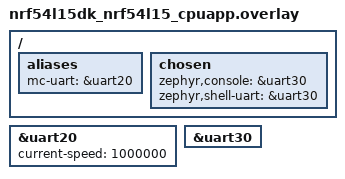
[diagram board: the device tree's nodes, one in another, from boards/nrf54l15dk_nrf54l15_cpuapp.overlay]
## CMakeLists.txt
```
# Copyright The Zephyr Project Contributors
# SPDX-License-Identifier: Apache-2.0

cmake_minimum_required(VERSION 3.28.0)
find_package(Zephyr REQUIRED HINTS $ENV{ZEPHYR_BASE})
project(mc_comm_stress)

target_sources(app PRIVATE
  src/main.c
)

if(CONFIG_TEST_MC_STRESS_UART)
  target_sources(app PRIVATE
    ../console_prefix.c
    src/transport_uart.c
  )
else()
  target_sources(app PRIVATE src/transport_native.c)
endif()
```

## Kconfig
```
# Copyright The Zephyr Project Contributors
# SPDX-License-Identifier: Apache-2.0

mainmenu "MC communication stress tests"

source "Kconfig.zephyr"

config TEST_MC_STRESS_UART
	bool "Use the two-board UART transport"
	depends on SERIAL
	help
	  Run the communication tests between two boards over UART.

config TEST_MC_STRESS_SENDER
	bool "Run the UART sender role"
	depends on TEST_MC_STRESS_UART
	help
	  Send test payloads to the receiver board.
```

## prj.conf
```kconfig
# Copyright The Zephyr Project Contributors
# SPDX-License-Identifier: Apache-2.0

CONFIG_ZTEST=y
CONFIG_MC=y
CONFIG_MC_COMM=y
CONFIG_MAIN_STACK_SIZE=8192
```

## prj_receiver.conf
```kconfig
# Copyright The Zephyr Project Contributors
# SPDX-License-Identifier: Apache-2.0

CONFIG_ZTEST=y
CONFIG_MC=y
CONFIG_MC_COMM=y
CONFIG_SERIAL=y
CONFIG_UART_INTERRUPT_DRIVEN=y
CONFIG_UART_CONSOLE=y
CONFIG_RING_BUFFER_LARGE=y
CONFIG_MAIN_STACK_SIZE=8192
CONFIG_TEST_MC_STRESS_UART=y
```

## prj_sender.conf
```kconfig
# Copyright The Zephyr Project Contributors
# SPDX-License-Identifier: Apache-2.0

CONFIG_ZTEST=y
CONFIG_MC=y
CONFIG_MC_COMM=y
CONFIG_SERIAL=y
CONFIG_UART_INTERRUPT_DRIVEN=y
CONFIG_RING_BUFFER_LARGE=y
CONFIG_MAIN_STACK_SIZE=8192
CONFIG_TEST_MC_STRESS_UART=y
CONFIG_TEST_MC_STRESS_SENDER=y
```

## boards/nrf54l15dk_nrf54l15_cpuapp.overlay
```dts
/*
 * SPDX-FileCopyrightText: Copyright The Zephyr Project Contributors
 * SPDX-License-Identifier: Apache-2.0
 */

/ {
	aliases {
		mc-uart = &uart20;
	};

	chosen {
		zephyr,console = &uart30;
		zephyr,shell-uart = &uart30;
	};
};

&uart20 {
	current-speed = <1000000>;
};

&uart30 {
	status = "okay";
};
```

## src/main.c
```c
/*
 * Copyright (c) 2026 Mahdi Sahebi
 *
 * SPDX-License-Identifier: Apache-2.0
 */

#include <errno.h>
#include <stdbool.h>
#include <stdint.h>
#include <string.h>

#include <zephyr/kernel.h>
#include <zephyr/mc/comm.h>
#include <zephyr/sys/printk.h>
#include <zephyr/ztest.h>

#include "transport.h"

#define TEST_STORAGE_SIZE 20000U
#define TEST_MESSAGE_SIZE 4096U
#define TEST_SEND_FRAME_SIZE 1157U
#define TEST_RECEIVE_FRAME_SIZE 59U
#define TEST_PHASE_SETTLE_MS    500U
#define TEST_STARTUP_TIMEOUT_US 300000000U

static uint8_t sender_storage[TEST_STORAGE_SIZE] __aligned(8);
static uint8_t receiver_storage[TEST_STORAGE_SIZE] __aligned(8);
static struct mc_comm *sender_comm;
static struct mc_comm *receiver_comm;
static uint8_t received[TEST_MESSAGE_SIZE];
static uint32_t words[1024];

static struct mc_comm_cfg make_config(bool sender, uint8_t retry_limit)
{
	struct mc_comm_cfg config = {
		.io.receive = stress_transport_receive,
		.io.transmit = stress_transport_transmit,
		.io.context = stress_transport_context(sender),
		.receive_capacity = TEST_MESSAGE_SIZE,
		.retry_limit = retry_limit,
		.send.size = sender ? TEST_SEND_FRAME_SIZE : TEST_RECEIVE_FRAME_SIZE,
		.recv.size = sender ? TEST_RECEIVE_FRAME_SIZE : TEST_SEND_FRAME_SIZE,
		.send.capacity = sender ? 3U : 1U,
		.recv.capacity = sender ? 2U : 4U,
	};

	return config;
}

static void init_pair(uint8_t loss_rate, bool duplicate, bool corrupt, bool shorten,
		      bool disconnect, uint8_t retry_limit)
{
	struct mc_comm_cfg sender_config;
	struct mc_comm_cfg receiver_config;

	zassert_ok(stress_transport_init(), NULL);
	stress_transport_reset(loss_rate, duplicate, corrupt, shorten, disconnect);
	sender_config = make_config(true, retry_limit);
	receiver_config = make_config(false, retry_limit);
	zassert_true(mc_comm_req_size(&sender_config) <= sizeof(sender_storage), NULL);
	zassert_true(mc_comm_req_size(&receiver_config) <= sizeof(receiver_storage), NULL);
	zassert_ok(mc_comm_init(&sender_comm, sender_storage, sizeof(sender_storage),
				&sender_config), NULL);
	zassert_ok(mc_comm_init(&receiver_comm, receiver_storage, sizeof(receiver_storage),
				&receiver_config), NULL);
	stress_transport_set_peer(true, receiver_comm);
	stress_transport_set_peer(false, sender_comm);
	if (IS_ENABLED(CONFIG_TEST_MC_STRESS_UART) &&
	    IS_ENABLED(CONFIG_TEST_MC_STRESS_SENDER)) {
		k_msleep(200U);
	}
}

static int exchange(const void *expected, size_t length, uint32_t timeout_us)
{
	size_t received_length = 0U;
	int err;

	if (!IS_ENABLED(CONFIG_TEST_MC_STRESS_UART) ||
	    IS_ENABLED(CONFIG_TEST_MC_STRESS_SENDER)) {
		err = mc_comm_send(sender_comm, expected, length, timeout_us);
		if (err != 0) {
			return err;
		}
	}
	if (!IS_ENABLED(CONFIG_TEST_MC_STRESS_UART) ||
	    !IS_ENABLED(CONFIG_TEST_MC_STRESS_SENDER)) {
		err = mc_comm_recv(receiver_comm, received, sizeof(received),
				      &received_length, timeout_us);
		if (err != 0) {
			return err;
		}
		if (received_length != length ||
		    (length > 0U && memcmp(received, expected, length) != 0)) {
			return -EBADMSG;
		}
	}
	return 0;
}

static size_t variadic_count(uint32_t seed)
{
	return (((seed * 1664525U) + 1013904223U) % 997U) + 27U;
}

static int transfer_iteration(uint32_t seed, uint32_t timeout_us)
{
	char string[9] = {0};
	bool tiny = (seed & 1U) != 0U;
	size_t count = variadic_count(seed);
	int err;

	(void)snprintk(string, sizeof(string), "!p%03u.?I", seed % 1000U);
	err = exchange(string, sizeof(string), timeout_us);
	if (err != 0) {
		return err;
	}
	for (size_t i = 0U; i < count; i++) {
		uint32_t coefficient = (i & 1U) != 0U ? 2654435761U : 40503U;

		words[i] = coefficient * (uint32_t)(i + 1U) * (seed + 1U) + (uint32_t)i;
	}
	err = exchange(words, count * sizeof(*words), timeout_us);
	if (err != 0) {
		return err;
	}
	return exchange(&tiny, sizeof(tiny), timeout_us);
}

static int finish_uart_phase(uint32_t timeout_us)
{
	const uint8_t marker = 0xa5U;
	int64_t deadline;
	int err = exchange(&marker, sizeof(marker), timeout_us);

	if (err != 0) {
		return err;
	}
	if (IS_ENABLED(CONFIG_TEST_MC_STRESS_SENDER)) {
		k_msleep(TEST_PHASE_SETTLE_MS);
		return 0;
	}

	deadline = k_uptime_get() + TEST_PHASE_SETTLE_MS;

	/* A final acknowledgment may be lost, so answer retransmissions before resetting. */
	while (k_uptime_get() < deadline) {
		err = mc_comm_update(receiver_comm);
		if (err != 0 && err != -EAGAIN && err != -EBADMSG) {
			return err;
		}
		k_msleep(1U);
	}
	return 0;
}

static int run_transfer(uint32_t iterations, uint8_t loss_rate, bool duplicate, bool corrupt,
			bool shorten, bool disconnect, bool allow_timeout, bool wait_for_peer)
{
	uint32_t timeout_us = allow_timeout ? 3000000U : 1000000U;
	uint8_t retry_limit = allow_timeout ? 100U : 30U;

	if (IS_ENABLED(CONFIG_TEST_MC_STRESS_UART) && !allow_timeout) {
		/* The two boards can enter a test phase at different times. */
		timeout_us = 5000000U;
	}

	init_pair(loss_rate, duplicate, corrupt, shorten, disconnect, retry_limit);
	if (loss_rate == 0U) {
		uint32_t first_timeout_us = timeout_us;
		int err;

		if (wait_for_peer && IS_ENABLED(CONFIG_TEST_MC_STRESS_UART) &&
		    !IS_ENABLED(CONFIG_TEST_MC_STRESS_SENDER)) {
			first_timeout_us = TEST_STARTUP_TIMEOUT_US;
		}
		err = exchange(NULL, 0U, first_timeout_us);

		if (err != 0) {
			return err;
		}
		for (size_t i = 0U; i < ARRAY_SIZE(words); i++) {
			words[i] = (uint32_t)i * 2654435761U;
		}
		err = exchange(words, sizeof(words), timeout_us);
		if (err != 0) {
			return err;
		}
	}
	for (uint32_t i = 0U; i < iterations; i++) {
		int err = transfer_iteration(i, timeout_us);

		if (err == -ETIMEDOUT && allow_timeout) {
			return 0;
		}
		if (err != 0) {
			return err;
		}
	}
	if (IS_ENABLED(CONFIG_TEST_MC_STRESS_UART) && !allow_timeout) {
		return finish_uart_phase(timeout_us);
	}
	return mc_comm_flush(IS_ENABLED(CONFIG_TEST_MC_STRESS_UART) &&
				     !IS_ENABLED(CONFIG_TEST_MC_STRESS_SENDER) ?
				     receiver_comm : sender_comm, timeout_us);
}

ZTEST(mc_comm_stress, test_01_invalid_creation)
{
	struct mc_comm_cfg config;

	zassert_ok(stress_transport_init(), NULL);
	config = make_config(true, 3U);
	config.io.receive = NULL;
	zassert_equal(mc_comm_req_size(&config), 0U, NULL);
	config = make_config(true, 3U);
	config.io.transmit = NULL;
	zassert_equal(mc_comm_req_size(&config), 0U, NULL);
	config = make_config(true, 3U);
	config.send.size = 12U;
	zassert_equal(mc_comm_req_size(&config), 0U, NULL);
	config = make_config(true, 3U);
	config.recv.capacity = 17U;
	zassert_equal(mc_comm_req_size(&config), 0U, NULL);
}

ZTEST(mc_comm_stress, test_02_invalid_argument)
{
	uint8_t data[10];
	size_t received_length;

	init_pair(0U, false, false, false, false, 3U);
	zassert_equal(mc_comm_send(NULL, data, sizeof(data), 100U), -EINVAL, NULL);
	zassert_equal(mc_comm_send(sender_comm, NULL, sizeof(data), 100U), -EINVAL, NULL);
	zassert_equal(mc_comm_recv(NULL, data, sizeof(data), &received_length, 100U),
		      -EINVAL, NULL);
	zassert_equal(mc_comm_recv(receiver_comm, NULL, sizeof(data), &received_length,
				      100U), -EINVAL, NULL);
	zassert_equal(mc_comm_update(NULL), -EINVAL, NULL);
	zassert_equal(mc_comm_flush(NULL, 100U), -EINVAL, NULL);
}

ZTEST(mc_comm_stress, test_03_valid_creation)
{
	struct mc_comm_cfg config;

	init_pair(0U, false, false, false, false, 3U);
	config = make_config(true, 3U);
	zassert_true(mc_comm_req_size(&config) > 0U, NULL);
	zassert_not_null(sender_comm, NULL);
	zassert_not_null(receiver_comm, NULL);
}

ZTEST(mc_comm_stress, test_04_singly_direction)
{
	uint32_t iterations = IS_ENABLED(CONFIG_TEST_MC_STRESS_UART) ? 200U : 20U;

	zassert_ok(run_transfer(iterations, 0U, false, false, false, false, false, true), NULL);
}

ZTEST(mc_comm_stress, test_05_singly_repetitive)
{
	uint32_t iterations = IS_ENABLED(CONFIG_TEST_MC_STRESS_UART) ? 200U : 20U;

	zassert_ok(run_transfer(iterations, 0U, true, false, false, false, false, false), NULL);
}

ZTEST(mc_comm_stress, test_06_singly_low_lossy)
{
	uint32_t iterations = IS_ENABLED(CONFIG_TEST_MC_STRESS_UART) ? 200U : 20U;

	zassert_ok(run_transfer(iterations, 20U, true, true, true, true, false, false), NULL);
}

ZTEST(mc_comm_stress, test_07_singly_high_lossy)
{
	uint32_t iterations = IS_ENABLED(CONFIG_TEST_MC_STRESS_UART) ? 100U : 3U;

	zassert_ok(run_transfer(iterations, 96U, true, true, true, true, true, false), NULL);
}

ZTEST(mc_comm_stress, test_08_singly_timed_out)
{
	uint8_t data[] = "timeout";
	uint8_t received[sizeof(data)];
	size_t length;

	init_pair(100U, false, false, false, false, 3U);
	if (!IS_ENABLED(CONFIG_TEST_MC_STRESS_UART) ||
	    IS_ENABLED(CONFIG_TEST_MC_STRESS_SENDER)) {
		zassert_equal(mc_comm_send(sender_comm, data, sizeof(data), 50000U),
			      -ETIMEDOUT, NULL);
	}
	if (!IS_ENABLED(CONFIG_TEST_MC_STRESS_UART) ||
	    !IS_ENABLED(CONFIG_TEST_MC_STRESS_SENDER)) {
		zassert_equal(mc_comm_recv(receiver_comm, received, sizeof(received),
					      &length, 50000U), -ETIMEDOUT, NULL);
	}
}

ZTEST_SUITE(mc_comm_stress, NULL, NULL, NULL, NULL, NULL);
```

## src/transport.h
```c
/*
 * Copyright (c) 2026 Mahdi Sahebi
 *
 * SPDX-License-Identifier: Apache-2.0
 */

#ifndef TESTS_SUBSYS_MC_COMM_STRESS_TRANSPORT_H_
#define TESTS_SUBSYS_MC_COMM_STRESS_TRANSPORT_H_

#include <stdbool.h>
#include <stddef.h>
#include <stdint.h>

#include <zephyr/mc/comm.h>

int stress_transport_init(void);
void stress_transport_reset(uint8_t loss_rate, bool duplicate, bool corrupt,
			    bool shorten, bool disconnect);
void *stress_transport_context(bool sender);
void stress_transport_set_peer(bool sender, struct mc_comm *peer);
int stress_transport_receive(void *context, uint8_t *data, size_t capacity);
int stress_transport_transmit(void *context, const uint8_t *data, size_t length);

#endif
```

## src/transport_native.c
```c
/*
 * Copyright (c) 2026 Mahdi Sahebi
 *
 * SPDX-License-Identifier: Apache-2.0
 */

#include <errno.h>
#include <string.h>

#include "transport.h"

#define LINK_CAPACITY 2048U

struct test_link {
	uint8_t data[LINK_CAPACITY];
	size_t length;
	bool full;
};

struct test_endpoint {
	struct test_link *incoming;
	struct test_link *outgoing;
	struct mc_comm *peer;
};

static struct test_link sender_to_receiver;
static struct test_link receiver_to_sender;
static struct test_endpoint sender_endpoint = {
	.incoming = &receiver_to_sender,
	.outgoing = &sender_to_receiver,
};
static struct test_endpoint receiver_endpoint = {
	.incoming = &sender_to_receiver,
	.outgoing = &receiver_to_sender,
};
static uint32_t random_state;
static uint32_t frame_count;
static uint8_t current_loss_rate;
static bool inject_duplicate;
static bool inject_corruption;
static bool inject_short_frame;
static bool inject_disconnection;

static uint32_t next_random(void)
{
	random_state = random_state * 1664525U + 1013904223U;
	return random_state;
}

int stress_transport_init(void)
{
	return 0;
}

void stress_transport_reset(uint8_t loss_rate, bool duplicate, bool corrupt,
			    bool shorten, bool disconnect)
{
	memset(&sender_to_receiver, 0, sizeof(sender_to_receiver));
	memset(&receiver_to_sender, 0, sizeof(receiver_to_sender));
	sender_endpoint.peer = NULL;
	receiver_endpoint.peer = NULL;
	random_state = 1U;
	frame_count = 0U;
	current_loss_rate = loss_rate;
	inject_duplicate = duplicate;
	inject_corruption = corrupt;
	inject_short_frame = shorten;
	inject_disconnection = disconnect;
}

void *stress_transport_context(bool sender)
{
	return sender ? (void *)&sender_endpoint : (void *)&receiver_endpoint;
}

void stress_transport_set_peer(bool sender, struct mc_comm *peer)
{
	if (sender) {
		sender_endpoint.peer = peer;
	} else {
		receiver_endpoint.peer = peer;
	}
}

int stress_transport_receive(void *context, uint8_t *data, size_t capacity)
{
	struct test_endpoint *endpoint = context;
	struct test_link *link = endpoint->incoming;

	if (!link->full) {
		return -EAGAIN;
	}
	if (capacity < link->length) {
		return -ENOSPC;
	}
	memcpy(data, link->data, link->length);
	link->full = false;
	return (int)link->length;
}

static void deliver(struct test_endpoint *endpoint, const uint8_t *data, size_t length)
{
	struct test_link *link = endpoint->outgoing;

	memcpy(link->data, data, length);
	link->length = length;
	link->full = true;
	if (endpoint->peer != NULL) {
		(void)mc_comm_update(endpoint->peer);
	}
}

int stress_transport_transmit(void *context, const uint8_t *data, size_t length)
{
	struct test_endpoint *endpoint = context;
	struct test_link *link = endpoint->outgoing;

	if (length > sizeof(link->data)) {
		return -EMSGSIZE;
	}
	if (link->full) {
		return -EAGAIN;
	}
	frame_count++;
	if ((inject_disconnection && frame_count % 32U < 8U) ||
	    (current_loss_rate > 0U && next_random() % 100U < current_loss_rate)) {
		return (int)length;
	}
	memcpy(link->data, data, length);
	link->length = length;
	if (inject_corruption && frame_count % 11U == 0U) {
		link->data[length - 1U] ^= 1U;
	}
	if (inject_short_frame && frame_count % 13U == 0U && length > 1U) {
		link->length--;
	}
	link->full = true;
	if (endpoint->peer != NULL) {
		(void)mc_comm_update(endpoint->peer);
	}
	if (inject_duplicate && frame_count % 7U == 0U && !link->full) {
		deliver(endpoint, data, length);
	}
	return (int)length;
}
```

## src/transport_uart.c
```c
/*
 * Copyright (c) 2026 Mahdi Sahebi
 *
 * SPDX-License-Identifier: Apache-2.0
 */

#include <errno.h>
#include <string.h>

#include <zephyr/device.h>
#include <zephyr/drivers/uart.h>
#include <zephyr/kernel.h>
#include <zephyr/sys/ring_buffer.h>

#include "transport.h"

#define MC_UART_NODE       DT_ALIAS(mc_uart)
#define UART_RING_SIZE     131072U
#define UART_FRAME_SIZE    2048U
#define UART_FRAME_END     0xc0U
#define UART_FRAME_ESCAPE  0xdbU
#define UART_ESCAPED_END   0xdcU
#define UART_ESCAPED_ESCAPE 0xddU

static const struct device *const uart = DEVICE_DT_GET(MC_UART_NODE);
RING_BUF_DECLARE(uart_ring, UART_RING_SIZE);
static uint8_t frame[UART_FRAME_SIZE];
static uint8_t send_frame[UART_FRAME_SIZE];
static size_t frame_length;
static bool frame_started;
static bool frame_escaped;
static bool frame_discarded;
static uint32_t random_state;
static uint32_t frame_count;
static uint8_t current_loss_rate;
static bool inject_duplicate;
static bool inject_corruption;
static bool inject_short_frame;
static bool inject_disconnection;

static uint32_t next_random(void)
{
	random_state = random_state * 1664525U + 1013904223U;
	return random_state;
}

static void uart_rx_callback(const struct device *device, void *user_data)
{
	uint8_t bytes[64];

	ARG_UNUSED(user_data);
	uart_irq_update(device);
	while (uart_irq_rx_ready(device)) {
		int length = uart_fifo_read(device, bytes, sizeof(bytes));

		if (length <= 0) {
			break;
		}
		(void)ring_buf_put(&uart_ring, bytes, (uint32_t)length);
	}
}

int stress_transport_init(void)
{
	if (!device_is_ready(uart)) {
		return -ENODEV;
	}
	int err = uart_irq_callback_user_data_set(uart, uart_rx_callback, NULL);

	if (err != 0) {
		return err;
	}
	uart_irq_rx_enable(uart);
	return 0;
}

void stress_transport_reset(uint8_t loss_rate, bool duplicate, bool corrupt,
			    bool shorten, bool disconnect)
{
	uart_irq_rx_disable(uart);
	ring_buf_reset(&uart_ring);
	uart_irq_rx_enable(uart);
	frame_length = 0U;
	frame_started = false;
	frame_escaped = false;
	frame_discarded = false;
	random_state = 1U;
	frame_count = 0U;
	current_loss_rate = loss_rate;
	inject_duplicate = duplicate;
	inject_corruption = corrupt;
	inject_short_frame = shorten;
	inject_disconnection = disconnect;
}

void *stress_transport_context(bool sender)
{
	ARG_UNUSED(sender);
	return NULL;
}

void stress_transport_set_peer(bool sender, struct mc_comm *peer)
{
	ARG_UNUSED(sender);
	ARG_UNUSED(peer);
}

int stress_transport_receive(void *context, uint8_t *data, size_t capacity)
{
	uint8_t byte;

	ARG_UNUSED(context);
	while (ring_buf_get(&uart_ring, &byte, 1U) == 1U) {
		if (byte == UART_FRAME_END) {
			if (frame_started && !frame_discarded && !frame_escaped &&
			    frame_length > 0U) {
				size_t length = frame_length;

				frame_length = 0U;
				if (length > capacity) {
					return -EMSGSIZE;
				}
				memcpy(data, frame, length);
				return (int)length;
			}
			frame_length = 0U;
			frame_started = true;
			frame_escaped = false;
			frame_discarded = false;
			continue;
		}
		if (!frame_started || frame_discarded) {
			continue;
		}
		if (frame_escaped) {
			frame_escaped = false;
			if (byte == UART_ESCAPED_END) {
				byte = UART_FRAME_END;
			} else if (byte == UART_ESCAPED_ESCAPE) {
				byte = UART_FRAME_ESCAPE;
			} else {
				frame_discarded = true;
				continue;
			}
		} else if (byte == UART_FRAME_ESCAPE) {
			frame_escaped = true;
			continue;
		}
		if (frame_length < sizeof(frame)) {
			frame[frame_length++] = byte;
		} else {
			frame_discarded = true;
		}
	}
	return -EAGAIN;
}

static void write_frame(const uint8_t *data, size_t length)
{
	uart_poll_out(uart, UART_FRAME_END);
	for (size_t i = 0U; i < length; i++) {
		if (data[i] == UART_FRAME_END || data[i] == UART_FRAME_ESCAPE) {
			uart_poll_out(uart, UART_FRAME_ESCAPE);
			uart_poll_out(uart, data[i] == UART_FRAME_END ?
					      UART_ESCAPED_END : UART_ESCAPED_ESCAPE);
		} else {
			uart_poll_out(uart, data[i]);
		}
	}
	uart_poll_out(uart, UART_FRAME_END);
}

int stress_transport_transmit(void *context, const uint8_t *data, size_t length)
{
	size_t original_length = length;

	ARG_UNUSED(context);
	if (length > sizeof(send_frame)) {
		return -EMSGSIZE;
	}
	frame_count++;
	if ((inject_disconnection && frame_count % 32U < 8U) ||
	    (current_loss_rate > 0U && next_random() % 100U < current_loss_rate)) {
		return (int)length;
	}
	memcpy(send_frame, data, length);
	if (inject_corruption && frame_count % 11U == 0U) {
		send_frame[length - 1U] ^= 1U;
	}
	if (inject_short_frame && frame_count % 13U == 0U && length > 1U) {
		length--;
	}
	write_frame(send_frame, length);
	if (inject_duplicate && frame_count % 7U == 0U) {
		k_msleep(5U);
		write_frame(send_frame, length);
	}
	return (int)original_length;
}
```
